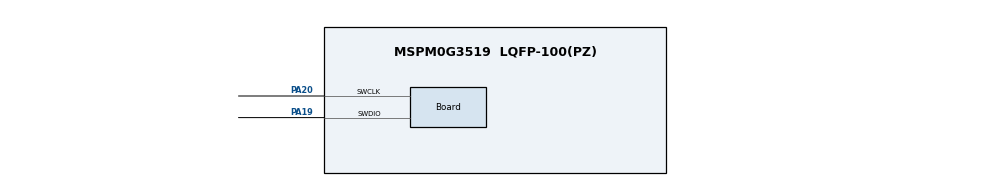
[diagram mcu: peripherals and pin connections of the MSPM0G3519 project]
//@cliArgs --device "MSPM0G351X" --package "LQFP-100(PZ)" --part "Default"
//@v2CliArgs --device "MSPM0G3519" --package "LQFP-100(PZ)"
// @cliArgs --board /ti/boards/LP_MSPM0G3519 --rtos nortos

/**
 * Import the modules used in this configuration.
 */
const CRCP   = scripting.addModule("/ti/driverlib/CRCP");
const SYSCTL = scripting.addModule("/ti/driverlib/SYSCTL");

/**
 * Write custom configuration values to the imported modules.
 */
CRCP.polynomial = "16_POLYNOMIAL_AUG_CCIT";
CRCP.endianness = "BIG_ENDIAN";
CRCP.seed       = 0xF1D;

const Board                       = scripting.addModule("/ti/driverlib/Board", {}, false);
Board.peripheral.$assign          = "DEBUGSS";
Board.peripheral.swclkPin.$assign = "PA20";
Board.peripheral.swdioPin.$assign = "PA19";

SYSCTL.forceDefaultClkConfig = true;
SYSCTL.clockTreeEn           = true;

const ProjectConfig              = scripting.addModule("/ti/project_config/ProjectConfig", {}, false);
ProjectConfig.migrationCondition = true;
